# MIMXRT685S_cm33 register map
Vendor: nxp.com; File version: 1.0
CPU: CM33 r2p0, little endian, MPU, FPU, VTOR, 3 interrupt priority bits
Registers are 32-bit, read-write, reset 0x0 unless marked. A register's access mark holds for its fields unless they carry their own. Offsets are from the block's base; [hi:lo] are bit positions; {n}, {i} and the like mark numbered series.

## PUF — PUF Controller
Base 0x40006000
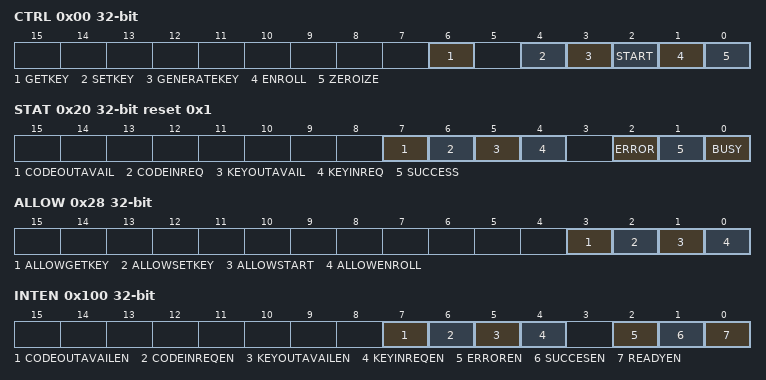
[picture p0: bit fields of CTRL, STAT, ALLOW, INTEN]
0x00 CTRL — PUF Control
  [6] GETKEY — Get Key. Begin Get Key operation
  [4] SETKEY — Set Key. Begin Set User Key operation
  [3] GENERATEKEY — Set Intrinsic Key. Begin Set Intrinsic Key operation
  [2] START — Start. Begin Start operation
  [1] ENROLL — Enroll. Begin Enroll operation
  [0] ZEROIZE — Zeroize. Begin Zeroize operation for Quiddikey and go to Error state
0x04 KEYINDEX — PUF Key Index
  [3:0] KEYIDX — Key index for Set Key operations
0x08 KEYSIZE — PUF Key Size
  [5:0] KEYSIZE — Key Size for Set Key operations
0x20 STAT ro reset 0x1 — PUF Status
  [7] CODEOUTAVAIL — Code Out Available
  [6] CODEINREQ — Code In Request
  [5] KEYOUTAVAIL — Key Out Available
  [4] KEYINREQ — Key In Request
  [2] ERROR
  [1] SUCCESS
  [0] BUSY
0x28 ALLOW ro — PUF Allow
  [3] ALLOWGETKEY, [2] ALLOWSETKEY, [1] ALLOWSTART, [0] ALLOWENROLL
0x40 KEYINPUT wo — PUF Key Input
  [31:0] KEYIN — Key Input Data
0x44 CODEINPUT wo — PUF Code Input
  [31:0] CODEIN — AC/KC Input Data
0x48 CODEOUTPUT ro — PUF Code Output
  [31:0] CODEOUT — AC/KC Output Data
0x60 KEYOUTINDEX ro — PUF Key Output Index
  [3:0] KEYOUTIDX — Key Output Index
0x64 KEYOUTPUT ro — PUF Key Output
  [31:0] KEYOUT — Key Output Data
0xDC IFSTAT write-1-clears — PUF Interface Status and Clear
  [0] ERROR write-1-clears
0xFC VERSION ro — PUF Version
0x100 INTEN — PUF Interrupt Enable
  [7] CODEOUTAVAILEN — Enable corresponding interrupt in STAT, which is next part of AC/KC is available.
  [6] CODEINREQEN — Enable corresponding interrupt in STAT, which is request for next part of AC/KC.
  [5] KEYOUTAVAILEN — Enable corresponding interrupt in STAT, which is next part of key is available.
  [4] KEYINREQEN — Enable corresponding interrupt in STAT, which is request for next part of key.
  [2] ERROREN — Enable corresponding interrupt in STAT, which indicates that PUF is in the error state and no operations can be performed.
  [1] SUCCESEN — Enable corresponding interrupt in STAT, which indicates last operation was successful.
  [0] READYEN — Enable corresponding interrupt in STAT, which indicates that the initialization or a operation is completed.
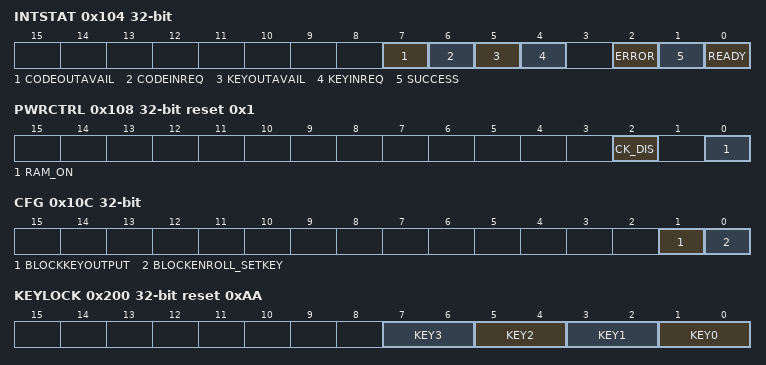
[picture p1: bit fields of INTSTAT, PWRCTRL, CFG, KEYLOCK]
0x104 INTSTAT — PUF Interrupt Status
  [7] CODEOUTAVAIL — Code Out Available
  [6] CODEINREQ — Code In Request
  [5] KEYOUTAVAIL — Key Out Available
  [4] KEYINREQ — Key In Request
  [2] ERROR
  [1] SUCCESS
  [0] READY write-1-clears
0x108 PWRCTRL reset 0x1 — PUF Power Control
  [2] CK_DIS — PUF Clock control.
    0=CLOCK_OFF (PUF RAM clock is disabled.); 1=CLOCK_ON (PUF RAM clock is enabled.)
  [0] RAM_ON — RAM Power On
    0=POWER_OFF; 1=POWER_ON
0x10C CFG — PUF Configuration
  [1] BLOCKKEYOUTPUT — Block Key Output Data
    0=DISABLED (Disabled. BLOCKKEYOUTPUT is cleared on reset.); 1=ENABLED
  [0] BLOCKENROLL_SETKEY — Block Enroll and Set Key Operation
    0=DISABLED; 1=ENABLED
0x200 KEYLOCK reset 0xAA
  [2n+1:2n] KEY{n} (n=0..3)
    0=KEY{n}LOCK_0 (Write access to KEY{n}MASK, KEYENABLE[KEY{n}] and KEYRESET[KEY{n}] is NOT allowed.); 1=KEY{n}LOCK_1 (Write access to KEY{n}MASK, KEYENABLE[KEY{n}] and KEYRESET[KEY{n}] is NOT allowed.); 2=KEY{n}UNLOCK (Write access to KEY{n}MASK, KEYENABLE[KEY{n}] and KEYRESET[KEY{n}] is allowed.); 3=KEY{n}LOCK_3 (Write access to KEY{n}MASK, KEYENABLE[KEY{n}] and KEYRESET[KEY{n}] is NOT allowed.)
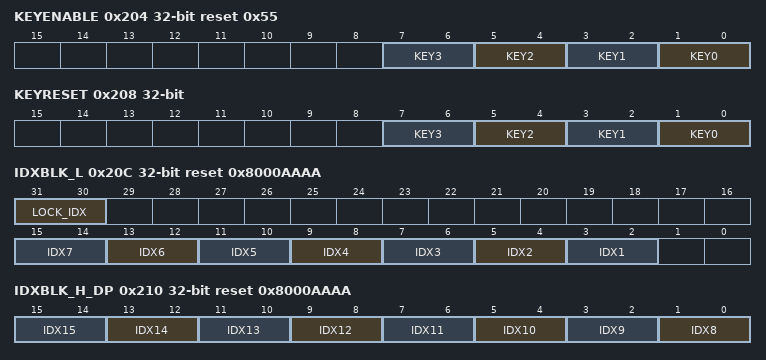
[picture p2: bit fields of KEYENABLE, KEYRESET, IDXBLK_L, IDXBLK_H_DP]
0x204 KEYENABLE reset 0x55
  [2n+1:2n] KEY{n} (n=0..3)
    0=DISABLED_0 (Data coming from the PUF Index 0 interface are NOT shifted in the KEY{n} register.); 1=DISABLED_1 (Data coming from the PUF Index 0 interface are NOT shifted in the KEY{n} register.); 2=ENABLED (Data coming from the PUF Index 0 interface are shifted in the KEY{n} register.); 3=DISABLED_3 (Data coming from the PUF Index 0 interface are NOT shifted in the KEY{n} register.)
0x208 KEYRESET wo
  [2n+1:2n] KEY{n} (n=0..3)
    2=RESET (Reset KEY{n} Hold register and SHIFT_STATUS[KEY{n}].)
0x20C IDXBLK_L reset 0x8000AAAA — Index Block Low
  [31:30] LOCK_IDX wo — Lock Index
  [2n+1:2n] IDX{n} (n=1..7) — Index {n}
0x210 IDXBLK_H_DP reset 0x8000AAAA — Index Block High Duplicate
  [2n-15:2n-16] IDX{n} (n=8..15) — Index {n}
{0x214+4i} KEYMASK[{i}] (i=0..1) wo — Key Mask x
  [31:0] KEYMASK — Key a Mask
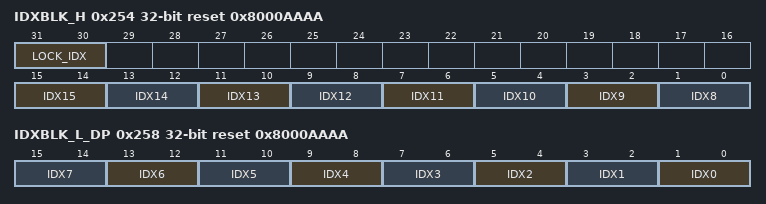
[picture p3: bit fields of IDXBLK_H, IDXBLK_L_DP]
0x254 IDXBLK_H reset 0x8000AAAA — Index Block High
  [31:30] LOCK_IDX — Lock Index
  [2n-15:2n-16] IDX{n} (n=8..15) — Index {n}
0x258 IDXBLK_L_DP reset 0x8000AAAA — Index Block Low Duplicate
  [2n+1:2n] IDX{n} (n=0..7) — Index {n}
